AUTOSAR XML (schema 00044)
package /ComponentTypes
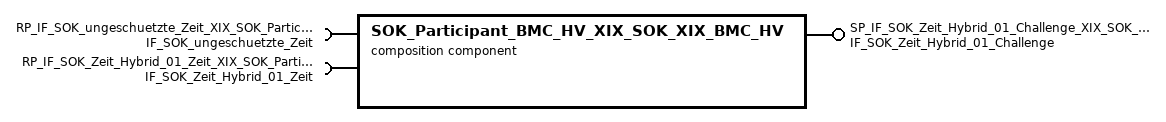
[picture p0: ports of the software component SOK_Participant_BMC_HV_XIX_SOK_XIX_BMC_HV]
  composition sw component type SOK_Participant_BMC_HV_XIX_SOK_XIX_BMC_HV
    provide port SP_IF_SOK_Zeit_Hybrid_01_Challenge_XIX_SOK_Participant_BMC_HV_XIX_SOK_XIX_BMC_HV: nonqueued-sender-com-spec=DE_SOK_Zeit_Hybrid_01_Challenge, provided-interface=IF_SOK_Zeit_Hybrid_01_Challenge
    require port RP_IF_SOK_ungeschuetzte_Zeit_XIX_SOK_Participant_BMC_HV_XIX_SOK_XIX_BMC_HV: nonqueued-receiver-com-spec=DE_SOK_ungeschuetzte_Zeit, required-interface=IF_SOK_ungeschuetzte_Zeit
    require port RP_IF_SOK_Zeit_Hybrid_01_Zeit_XIX_SOK_Participant_BMC_HV_XIX_SOK_XIX_BMC_HV: nonqueued-receiver-com-spec=DE_SOK_Zeit_Hybrid_01_Zeit, required-interface=IF_SOK_Zeit_Hybrid_01_Zeit
